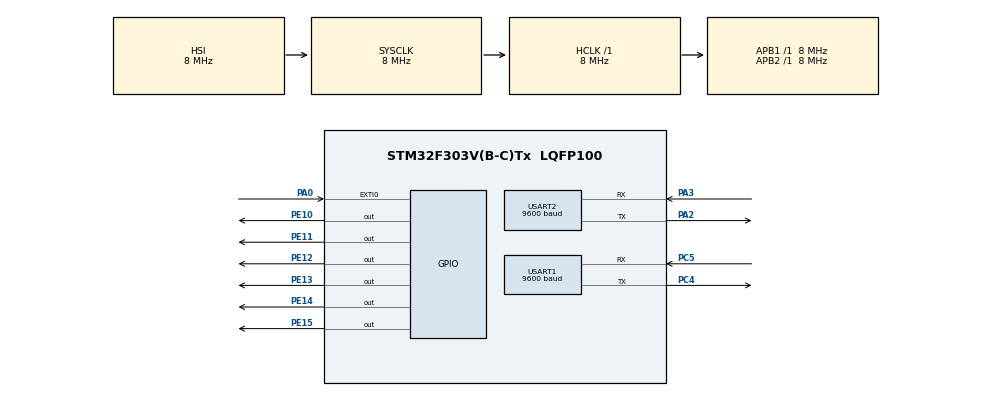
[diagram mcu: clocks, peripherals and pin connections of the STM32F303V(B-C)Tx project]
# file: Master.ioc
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Mcu.Family=STM32F3
Mcu.Name=STM32F303V(B-C)Tx
Mcu.Package=LQFP100
NVIC.PriorityGroup=NVIC_PRIORITYGROUP_4
NVIC.USART1_IRQn=true\:1\:0\:true\:false\:true\:true\:true\:true
NVIC.USART2_IRQn=true\:2\:0\:true\:false\:true\:true\:true\:true
PA0.Signal=GPXTI0
PA2.Mode=Asynchronous
PA2.Signal=USART2_TX
PA3.Mode=Asynchronous
PA3.Signal=USART2_RX
PC4.Mode=Asynchronous
PC4.Signal=USART1_TX
PC5.Mode=Asynchronous
PC5.Signal=USART1_RX
PE10.Signal=GPIO_Output
PE11.Signal=GPIO_Output
PE12.Signal=GPIO_Output
PE13.Signal=GPIO_Output
PE14.Signal=GPIO_Output
PE15.Signal=GPIO_Output
ProjectManager.HeapSize=0x200
ProjectManager.StackSize=0x400
ProjectManager.TargetToolchain=STM32CubeIDE
RCC.AHBFreq_Value=8000000
RCC.APB1Freq_Value=8000000
RCC.APB2Freq_Value=8000000
RCC.CortexFreq_Value=8000000
RCC.HSE_VALUE=8000000
RCC.HSI_VALUE=8000000
RCC.LSE_VALUE=32768
RCC.SYSCLKFreq_VALUE=8000000
USART1.BaudRate=9600
USART1.VirtualMode-Asynchronous=VM_ASYNC
USART2.BaudRate=9600
USART2.VirtualMode-Asynchronous=VM_ASYNC
board=custom

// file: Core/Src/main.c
/* USER CODE BEGIN Header */
/**
  ******************************************************************************
  * @file           : main.c
  * @brief          : Main program body
  ******************************************************************************
  * @attention
  *
  * Copyright (c) 2023 STMicroelectronics.
  * All rights reserved.
  *
  * This software is licensed under terms that can be found in the LICENSE file
  * in the root directory of this software component.
  * If no LICENSE file comes with this software, it is provided AS-IS.
  *
  ******************************************************************************
  */
/* USER CODE END Header */
#include "main.h"
#include <stdbool.h>
#include <string.h>
#include "../LIBR/Metodi/ManageStr.h"
#define BUFFER_LEN  1
#define BUFFER_SIZE 50
#define stop  115

uint8_t RX_BUFFER[BUFFER_LEN] = {0};
uint8_t RX_BUFFER1[BUFFER_LEN] = {0};

uint8_t rx_buffer[BUFFER_SIZE];
int rx_index = 0;
bool rx_complete = false;

uint8_t rx_buffer1[BUFFER_SIZE];
int rx_index1 = 0;
bool rx_complete1 = false;

UART_HandleTypeDef huart1;
UART_HandleTypeDef huart2;

void SystemClock_Config(void);
static void MX_GPIO_Init(void);
static void MX_USART1_UART_Init(void);
static void MX_USART2_UART_Init(void);

float temp0=0,temp1=0,hmdy0=0,hmdy1=0;
Stringa_TypeDef valS0,valS1;
void HAL_UART_RxCpltCallback(UART_HandleTypeDef *huart)
{
    if(huart->Instance == huart1.Instance)
    {
    HAL_UART_Receive_IT(&huart1, RX_BUFFER, BUFFER_LEN);

    if (RX_BUFFER[0] == stop) {
               rx_complete = true;
    			valS1=CutString(&rx_buffer);
    	    	 temp0=valS1.Temp;
    	    	 hmdy0=valS1.Hmdy;
    	    	rx_index = 0;
           } else {
               rx_buffer[rx_index] = RX_BUFFER[0];
               rx_index++;
           }

    }
    if(huart->Instance == huart2.Instance)
       {
       HAL_UART_Receive_IT(&huart2, RX_BUFFER1, BUFFER_LEN);
       if (RX_BUFFER1[0] == stop) {
                   rx_complete1 = true;
    	   	   	   valS1=CutString(&rx_buffer1);
    	       	    temp1=valS1.Temp;
    	       	    hmdy1=valS1.Hmdy;
    	       	   rx_index1 = 0;
                } else {
                    rx_buffer1[rx_index1] = RX_BUFFER1[0];
                    rx_index1++;
                }
       }
}

int main(void)
{

  /* MCU Configuration--------------------------------------------------------*/

  /* Reset of all peripherals, Initializes the Flash interface and the Systick. */
  HAL_Init();

  /* Configure the system clock */
  SystemClock_Config();

  /* Initialize all configured peripherals */
  MX_GPIO_Init();
  MX_USART1_UART_Init();
  MX_USART2_UART_Init();
  /* USER CODE BEGIN 2 */
  HAL_UART_Receive_IT(&huart2, RX_BUFFER1, BUFFER_LEN);
  HAL_UART_Receive_IT(&huart1, RX_BUFFER, BUFFER_LEN);
  /* USER CODE END 2 */

  /* Infinite loop */
  /* USER CODE BEGIN WHILE */
  char bufferH[10],bufferT[10];
  while (1)
  {
    /* USER CODE END WHILE */
    if(rx_complete == true &&  rx_complete1 == true){

    	    float Temp=(temp0+temp1)/2;
    	    float Hmdy=(hmdy0+hmdy1)/2;

    	    HAL_GPIO_WritePin(GPIOE, GPIO_PIN_10|GPIO_PIN_11|GPIO_PIN_12|GPIO_PIN_13
    	                            |GPIO_PIN_14|GPIO_PIN_15, GPIO_PIN_SET);

    	    //Trasmissione Temp
    	                			sprintf(bufferT, "TMP:");
    	                			HAL_UART_Transmit(&huart1, (uint8_t*)bufferT, strlen(bufferT), HAL_MAX_DELAY);
    	                			gcvt(Temp, sizeof(Temp), bufferT);
    	                			HAL_UART_Transmit(&huart1, (uint8_t*)bufferT, strlen(bufferT), HAL_MAX_DELAY);
    	                			sprintf(bufferT, "\r");
    	                			HAL_UART_Transmit(&huart1, (uint8_t*)bufferT, strlen(bufferT), HAL_MAX_DELAY);

    	                			//Trasmissione Umidità
    	                			sprintf(bufferH, "HDY:");
    	                			HAL_UART_Transmit(&huart1, (uint8_t*)bufferH, strlen(bufferH), HAL_MAX_DELAY);
    	                			gcvt(Hmdy, sizeof(Hmdy), bufferH);
    	                			HAL_UART_Transmit(&huart1, (uint8_t*)bufferH, strlen(bufferH), HAL_MAX_DELAY);
    	                			sprintf(bufferH, "\r\n");
    	                			HAL_UART_Transmit(&huart1, (uint8_t*)bufferH, strlen(bufferH), HAL_MAX_DELAY);

    	                			 //Trasmissione Temp
    	                			    	                			sprintf(bufferT, "TMP:");
    	                			    	                			HAL_UART_Transmit(&huart2, (uint8_t*)bufferT, strlen(bufferT), HAL_MAX_DELAY);
    	                			    	                			gcvt(Temp, sizeof(Temp), bufferT);
    	                			    	                			HAL_UART_Transmit(&huart2, (uint8_t*)bufferT, strlen(bufferT), HAL_MAX_DELAY);
    	                			    	                			sprintf(bufferT, "\r");
    	                			    	                			HAL_UART_Transmit(&huart2, (uint8_t*)bufferT, strlen(bufferT), HAL_MAX_DELAY);

    	                			    	                			//Trasmissione Umidità
    	                			    	                			sprintf(bufferH, "HDY:");
    	                			    	                			HAL_UART_Transmit(&huart2, (uint8_t*)bufferH, strlen(bufferH), HAL_MAX_DELAY);
    	                			    	                			gcvt(Hmdy, sizeof(Hmdy), bufferH);
    	                			    	                			HAL_UART_Transmit(&huart2, (uint8_t*)bufferH, strlen(bufferH), HAL_MAX_DELAY);
    	                			    	                			sprintf(bufferH, "\r\n");
    	                			    	                			HAL_UART_Transmit(&huart2, (uint8_t*)bufferH, strlen(bufferH), HAL_MAX_DELAY);

    	    rx_complete =false;
    	    rx_complete1 =false;

    }

  }
}

void SystemClock_Config(void)
{
  RCC_OscInitTypeDef RCC_OscInitStruct = {0};
  RCC_ClkInitTypeDef RCC_ClkInitStruct = {0};
  RCC_PeriphCLKInitTypeDef PeriphClkInit = {0};

  /** Initializes the RCC Oscillators according to the specified parameters
  * in the RCC_OscInitTypeDef structure.
  */
  RCC_OscInitStruct.OscillatorType = RCC_OSCILLATORTYPE_HSI;
  RCC_OscInitStruct.HSIState = RCC_HSI_ON;
  RCC_OscInitStruct.HSICalibrationValue = RCC_HSICALIBRATION_DEFAULT;
  RCC_OscInitStruct.PLL.PLLState = RCC_PLL_NONE;
  if (HAL_RCC_OscConfig(&RCC_OscInitStruct) != HAL_OK)
  {
    Error_Handler();
  }

  /** Initializes the CPU, AHB and APB buses clocks
  */
  RCC_ClkInitStruct.ClockType = RCC_CLOCKTYPE_HCLK|RCC_CLOCKTYPE_SYSCLK
                              |RCC_CLOCKTYPE_PCLK1|RCC_CLOCKTYPE_PCLK2;
  RCC_ClkInitStruct.SYSCLKSource = RCC_SYSCLKSOURCE_HSI;
  RCC_ClkInitStruct.AHBCLKDivider = RCC_SYSCLK_DIV1;
  RCC_ClkInitStruct.APB1CLKDivider = RCC_HCLK_DIV1;
  RCC_ClkInitStruct.APB2CLKDivider = RCC_HCLK_DIV1;

  if (HAL_RCC_ClockConfig(&RCC_ClkInitStruct, FLASH_LATENCY_0) != HAL_OK)
  {
    Error_Handler();
  }
  PeriphClkInit.PeriphClockSelection = RCC_PERIPHCLK_USART1|RCC_PERIPHCLK_USART2;
  PeriphClkInit.Usart1ClockSelection = RCC_USART1CLKSOURCE_PCLK2;
  PeriphClkInit.Usart2ClockSelection = RCC_USART2CLKSOURCE_PCLK1;
  if (HAL_RCCEx_PeriphCLKConfig(&PeriphClkInit) != HAL_OK)
  {
    Error_Handler();
  }
}

static void MX_USART1_UART_Init(void)
{

  huart1.Instance = USART1;
  huart1.Init.BaudRate = 9600;
  huart1.Init.WordLength = UART_WORDLENGTH_8B;
  huart1.Init.StopBits = UART_STOPBITS_1;
  huart1.Init.Parity = UART_PARITY_NONE;
  huart1.Init.Mode = UART_MODE_TX_RX;
  huart1.Init.HwFlowCtl = UART_HWCONTROL_NONE;
  huart1.Init.OverSampling = UART_OVERSAMPLING_16;
  huart1.Init.OneBitSampling = UART_ONE_BIT_SAMPLE_DISABLE;
  huart1.AdvancedInit.AdvFeatureInit = UART_ADVFEATURE_NO_INIT;
  if (HAL_UART_Init(&huart1) != HAL_OK)
  {
    Error_Handler();
  }

}

static void MX_USART2_UART_Init(void)
{

  huart2.Instance = USART2;
  huart2.Init.BaudRate = 9600;
  huart2.Init.WordLength = UART_WORDLENGTH_8B;
  huart2.Init.StopBits = UART_STOPBITS_1;
  huart2.Init.Parity = UART_PARITY_NONE;
  huart2.Init.Mode = UART_MODE_TX_RX;
  huart2.Init.HwFlowCtl = UART_HWCONTROL_NONE;
  huart2.Init.OverSampling = UART_OVERSAMPLING_16;
  huart2.Init.OneBitSampling = UART_ONE_BIT_SAMPLE_DISABLE;
  huart2.AdvancedInit.AdvFeatureInit = UART_ADVFEATURE_NO_INIT;
  if (HAL_UART_Init(&huart2) != HAL_OK)
  {
    Error_Handler();
  }

}

static void MX_GPIO_Init(void)
{
  GPIO_InitTypeDef GPIO_InitStruct = {0};

  /* GPIO Ports Clock Enable */
  __HAL_RCC_GPIOA_CLK_ENABLE();
  __HAL_RCC_GPIOC_CLK_ENABLE();
  __HAL_RCC_GPIOE_CLK_ENABLE();

  /*Configure GPIO pin Output Level */
  HAL_GPIO_WritePin(GPIOE, GPIO_PIN_10|GPIO_PIN_11|GPIO_PIN_12|GPIO_PIN_13
                          |GPIO_PIN_14|GPIO_PIN_15, GPIO_PIN_RESET);

  /*Configure GPIO pin : PA0 */
  GPIO_InitStruct.Pin = GPIO_PIN_0;
  GPIO_InitStruct.Mode = GPIO_MODE_IT_RISING;
  GPIO_InitStruct.Pull = GPIO_NOPULL;
  HAL_GPIO_Init(GPIOA, &GPIO_InitStruct);

  /*Configure GPIO pins : PE10 PE11 PE12 PE13
                           PE14 PE15 */
  GPIO_InitStruct.Pin = GPIO_PIN_10|GPIO_PIN_11|GPIO_PIN_12|GPIO_PIN_13
                          |GPIO_PIN_14|GPIO_PIN_15;
  GPIO_InitStruct.Mode = GPIO_MODE_OUTPUT_PP;
  GPIO_InitStruct.Pull = GPIO_NOPULL;
  GPIO_InitStruct.Speed = GPIO_SPEED_FREQ_LOW;
  HAL_GPIO_Init(GPIOE, &GPIO_InitStruct);

}

void Error_Handler(void)
{
  __disable_irq();
  while (1)
  {
  }
}
